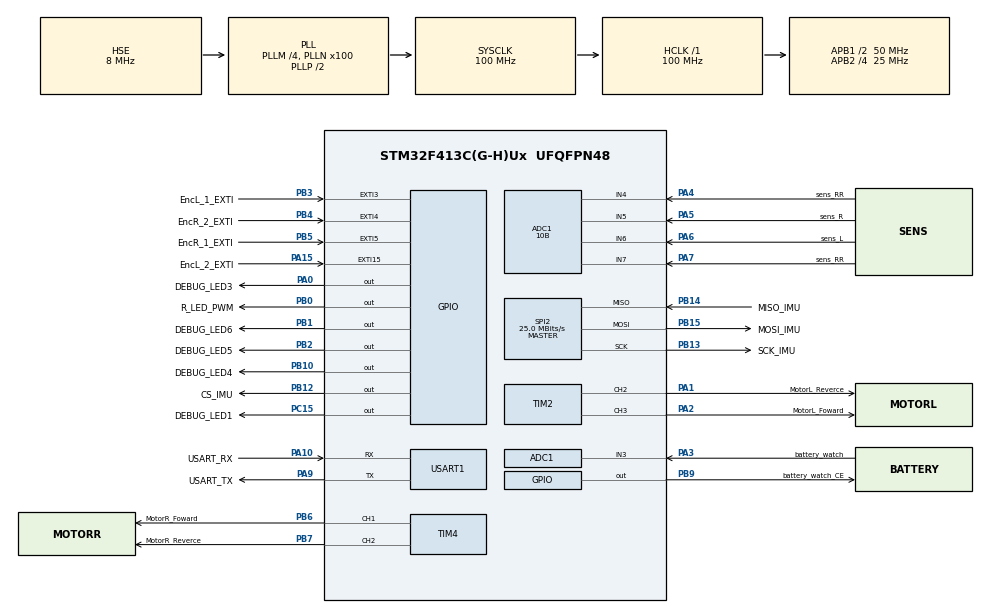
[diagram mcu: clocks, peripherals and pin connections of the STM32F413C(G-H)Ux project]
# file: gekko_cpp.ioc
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ADC1.Channel-0\#ChannelRegularConversion=ADC_CHANNEL_3
ADC1.Channel-1\#ChannelInjectedConversion=ADC_CHANNEL_3
ADC1.Channel-5\#ChannelRegularConversion=ADC_CHANNEL_3
ADC1.Channel-6\#ChannelRegularConversion=ADC_CHANNEL_3
ADC1.Channel-7\#ChannelRegularConversion=ADC_CHANNEL_3
ADC1.Channel-8\#ChannelRegularConversion=ADC_CHANNEL_3
ADC1.DiscontinuousConvMode=DISABLE
ADC1.InjNumberOfConversion=1
ADC1.InjectedOffset-1\#ChannelInjectedConversion=0
ADC1.InjectedRank-1\#ChannelInjectedConversion=1
ADC1.NbrOfConversion=5
ADC1.NbrOfConversionFlag=1
ADC1.Rank-0\#ChannelRegularConversion=1
ADC1.Rank-5\#ChannelRegularConversion=2
ADC1.Rank-6\#ChannelRegularConversion=3
ADC1.Rank-7\#ChannelRegularConversion=4
ADC1.Rank-8\#ChannelRegularConversion=5
ADC1.Resolution=ADC_RESOLUTION_10B
ADC1.SamplingTime-0\#ChannelRegularConversion=ADC_SAMPLETIME_3CYCLES
ADC1.SamplingTime-1\#ChannelInjectedConversion=ADC_SAMPLETIME_3CYCLES
ADC1.SamplingTime-5\#ChannelRegularConversion=ADC_SAMPLETIME_3CYCLES
ADC1.SamplingTime-6\#ChannelRegularConversion=ADC_SAMPLETIME_3CYCLES
ADC1.SamplingTime-7\#ChannelRegularConversion=ADC_SAMPLETIME_3CYCLES
ADC1.SamplingTime-8\#ChannelRegularConversion=ADC_SAMPLETIME_3CYCLES
ADC1.ScanConvMode=ENABLE
ADC1.master=1
Dma.ADC1.0.Direction=DMA_PERIPH_TO_MEMORY
Dma.ADC1.0.FIFOMode=DMA_FIFOMODE_DISABLE
Dma.ADC1.0.Instance=DMA2_Stream0
Dma.ADC1.0.MemDataAlignment=DMA_MDATAALIGN_HALFWORD
Dma.ADC1.0.MemInc=DMA_MINC_ENABLE
Dma.ADC1.0.Mode=DMA_NORMAL
Dma.ADC1.0.PeriphDataAlignment=DMA_PDATAALIGN_HALFWORD
Dma.ADC1.0.PeriphInc=DMA_PINC_DISABLE
Dma.ADC1.0.Priority=DMA_PRIORITY_LOW
Dma.Request0=ADC1
Mcu.Family=STM32F4
Mcu.Name=STM32F413C(G-H)Ux
Mcu.Package=UFQFPN48
NVIC.DMA2_Stream0_IRQn=true\:0\:0\:false\:false\:true\:false\:true
NVIC.PriorityGroup=NVIC_PRIORITYGROUP_4
PA0.GPIO_Label=DEBUG_LED3
PA0.Signal=GPIO_Output
PA1.GPIO_Label=MotorL_Reverce
PA1.Signal=S_TIM2_CH2
PA10.GPIO_Label=USART_RX
PA10.Mode=Asynchronous
PA10.Signal=USART1_RX
PA13.Mode=Serial_Wire
PA13.Signal=SYS_JTMS-SWDIO
PA14.Mode=Serial_Wire
PA14.Signal=SYS_JTCK-SWCLK
PA15.GPIO_Label=EncL_2_EXTI
PA15.Signal=GPXTI15
PA2.GPIO_Label=MotorL_Foward
PA2.Signal=S_TIM2_CH3
PA3.GPIO_Label=battery_watch
PA3.Signal=ADCx_IN3
PA4.GPIO_Label=sens_RR
PA4.Signal=ADCx_IN4
PA5.GPIO_Label=sens_R
PA5.Signal=ADCx_IN5
PA6.GPIO_Label=sens_L
PA6.Signal=ADCx_IN6
PA7.GPIO_Label=sens_RR
PA7.Signal=ADCx_IN7
PA9.GPIO_Label=USART_TX
PA9.Mode=Asynchronous
PA9.Signal=USART1_TX
PB0.GPIO_Label=R_LED_PWM
PB0.Signal=GPIO_Output
PB1.GPIO_Label=DEBUG_LED6
PB1.Signal=GPIO_Output
PB10.GPIO_Label=DEBUG_LED4
PB10.Signal=GPIO_Output
PB12.GPIO_Label=CS_IMU
PB12.Signal=GPIO_Output
PB13.GPIO_Label=SCK_IMU
PB13.Mode=Full_Duplex_Master
PB13.Signal=SPI2_SCK
PB14.GPIO_Label=MISO_IMU
PB14.Mode=Full_Duplex_Master
PB14.Signal=SPI2_MISO
PB15.GPIO_Label=MOSI_IMU
PB15.Mode=Full_Duplex_Master
PB15.Signal=SPI2_MOSI
PB2.GPIO_Label=DEBUG_LED5
PB2.Signal=GPIO_Output
PB3.GPIO_Label=EncL_1_EXTI
PB3.Signal=GPXTI3
PB4.GPIO_Label=EncR_2_EXTI
PB4.Signal=GPXTI4
PB5.GPIO_Label=EncR_1_EXTI
PB5.Signal=GPXTI5
PB6.GPIO_Label=MotorR_Foward
PB6.Signal=S_TIM4_CH1
PB7.GPIO_Label=MotorR_Reverce
PB7.Signal=S_TIM4_CH2
PB9.GPIO_Label=battery_watch_CE
PB9.Signal=GPIO_Output
PC15-OSC32_OUT.GPIO_Label=DEBUG_LED1
PC15-OSC32_OUT.Signal=GPIO_Output
PH0\ -\ OSC_IN.Mode=HSE-External-Oscillator
PH0\ -\ OSC_IN.Signal=RCC_OSC_IN
PH1\ -\ OSC_OUT.Mode=HSE-External-Oscillator
PH1\ -\ OSC_OUT.Signal=RCC_OSC_OUT
ProjectManager.HeapSize=0x200
ProjectManager.StackSize=0x400
ProjectManager.TargetToolchain=STM32CubeIDE
RCC.AHBFreq_Value=100000000
RCC.APB1CLKDivider=RCC_HCLK_DIV2
RCC.APB1Freq_Value=50000000
RCC.APB1TimFreq_Value=100000000
RCC.APB2CLKDivider=RCC_HCLK_DIV4
RCC.APB2Freq_Value=25000000
RCC.APB2TimFreq_Value=50000000
RCC.CortexFreq_Value=100000000
RCC.DATA_CACHE_ENABLE=1
RCC.HCLKFreq_Value=100000000
RCC.HSE_VALUE=8000000
RCC.PLLM=4
RCC.PLLN=100
RCC.PLLSourceVirtual=RCC_PLLSOURCE_HSE
RCC.PREFETCH_ENABLE=1
RCC.RCC_TIM_PRescaler_Selection=RCC_TIMPRES_DESACTIVATED
RCC.SYSCLKFreq_VALUE=100000000
RCC.SYSCLKSource=RCC_SYSCLKSOURCE_PLLCLK
RCC.USBFreq_Value=100000000
RCC.VCOOutputFreq_Value=200000000
SH.ADCx_IN3.0=ADC1_IN3,IN3
SH.ADCx_IN4.0=ADC1_IN4,IN4
SH.ADCx_IN5.0=ADC1_IN5,IN5
SH.ADCx_IN6.0=ADC1_IN6,IN6
SH.ADCx_IN7.0=ADC1_IN7,IN7
SH.S_TIM2_CH2.0=TIM2_CH2,PWM Generation2 CH2
SH.S_TIM2_CH3.0=TIM2_CH3,PWM Generation3 CH3
SH.S_TIM4_CH1.0=TIM4_CH1,PWM Generation1 CH1
SH.S_TIM4_CH2.0=TIM4_CH2,PWM Generation2 CH2
SPI2.BaudRatePrescaler=SPI_BAUDRATEPRESCALER_2
SPI2.CalculateBaudRate=25.0 MBits/s
SPI2.Direction=SPI_DIRECTION_2LINES
SPI2.Mode=SPI_MODE_MASTER
SPI2.VirtualType=VM_MASTER
TIM2.Channel-PWM\ Generation2\ CH2=TIM_CHANNEL_2
TIM2.Channel-PWM\ Generation3\ CH3=TIM_CHANNEL_3
TIM4.Channel-PWM\ Generation1\ CH1=TIM_CHANNEL_1
TIM4.Channel-PWM\ Generation2\ CH2=TIM_CHANNEL_2
USART1.VirtualMode=VM_ASYNC
board=custom

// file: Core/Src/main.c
/* USER CODE BEGIN Header */
/**
  ******************************************************************************
  * @file           : main.c
  * @brief          : Main program body
  ******************************************************************************
  * @attention
  *
  * <h2><center>&copy; Copyright (c) 2020 STMicroelectronics.
  * All rights reserved.</center></h2>
  *
  * This software component is licensed by ST under BSD 3-Clause license,
  * the "License"; You may not use this file except in compliance with the
  * License. You may obtain a copy of the License at:
  *                        opensource.org/licenses/BSD-3-Clause
  *
  ******************************************************************************
  */
/* USER CODE END Header */

#include "main.h"

ADC_HandleTypeDef hadc1;
DMA_HandleTypeDef hdma_adc1;

SPI_HandleTypeDef hspi2;

TIM_HandleTypeDef htim2;
TIM_HandleTypeDef htim4;

UART_HandleTypeDef huart1;

void SystemClock_Config(void);
static void MX_GPIO_Init(void);
static void MX_DMA_Init(void);
static void MX_ADC1_Init(void);
static void MX_SPI2_Init(void);
static void MX_TIM2_Init(void);
static void MX_TIM4_Init(void);
static void MX_USART1_UART_Init(void);

int main(void)
{

  /* MCU Configuration--------------------------------------------------------*/

  /* Reset of all peripherals, Initializes the Flash interface and the Systick. */
  HAL_Init();

  /* Configure the system clock */
  SystemClock_Config();

  /* Initialize all configured peripherals */
  MX_GPIO_Init();
  MX_DMA_Init();
  MX_ADC1_Init();
  MX_SPI2_Init();
  MX_TIM2_Init();
  MX_TIM4_Init();
  MX_USART1_UART_Init();

  /* Infinite loop */
  while (1)
  {

    /* USER CODE BEGIN 3 */
	  HAL_GPIO_TogglePin(GPIOB, DEBUG_LED5_Pin);
	  HAL_Delay(100);

  }
  /* USER CODE END 3 */
}

void SystemClock_Config(void)
{
  RCC_OscInitTypeDef RCC_OscInitStruct = {0};
  RCC_ClkInitTypeDef RCC_ClkInitStruct = {0};

  /** Configure the main internal regulator output voltage
  */
  __HAL_RCC_PWR_CLK_ENABLE();
  __HAL_PWR_VOLTAGESCALING_CONFIG(PWR_REGULATOR_VOLTAGE_SCALE1);
  /** Initializes the CPU, AHB and APB busses clocks
  */
  RCC_OscInitStruct.OscillatorType = RCC_OSCILLATORTYPE_HSE;
  RCC_OscInitStruct.HSEState = RCC_HSE_ON;
  RCC_OscInitStruct.PLL.PLLState = RCC_PLL_ON;
  RCC_OscInitStruct.PLL.PLLSource = RCC_PLLSOURCE_HSE;
  RCC_OscInitStruct.PLL.PLLM = 4;
  RCC_OscInitStruct.PLL.PLLN = 100;
  RCC_OscInitStruct.PLL.PLLP = RCC_PLLP_DIV2;
  RCC_OscInitStruct.PLL.PLLQ = 2;
  RCC_OscInitStruct.PLL.PLLR = 2;
  if (HAL_RCC_OscConfig(&RCC_OscInitStruct) != HAL_OK)
  {
    Error_Handler();
  }
  /** Initializes the CPU, AHB and APB busses clocks
  */
  RCC_ClkInitStruct.ClockType = RCC_CLOCKTYPE_HCLK|RCC_CLOCKTYPE_SYSCLK
                              |RCC_CLOCKTYPE_PCLK1|RCC_CLOCKTYPE_PCLK2;
  RCC_ClkInitStruct.SYSCLKSource = RCC_SYSCLKSOURCE_PLLCLK;
  RCC_ClkInitStruct.AHBCLKDivider = RCC_SYSCLK_DIV1;
  RCC_ClkInitStruct.APB1CLKDivider = RCC_HCLK_DIV2;
  RCC_ClkInitStruct.APB2CLKDivider = RCC_HCLK_DIV4;

  if (HAL_RCC_ClockConfig(&RCC_ClkInitStruct, FLASH_LATENCY_3) != HAL_OK)
  {
    Error_Handler();
  }
}

static void MX_ADC1_Init(void)
{

  ADC_ChannelConfTypeDef sConfig = {0};
  ADC_InjectionConfTypeDef sConfigInjected = {0};

  /** Configure the global features of the ADC (Clock, Resolution, Data Alignment and number of conversion)
  */
  hadc1.Instance = ADC1;
  hadc1.Init.ClockPrescaler = ADC_CLOCK_SYNC_PCLK_DIV2;
  hadc1.Init.Resolution = ADC_RESOLUTION_10B;
  hadc1.Init.ScanConvMode = ENABLE;
  hadc1.Init.ContinuousConvMode = DISABLE;
  hadc1.Init.DiscontinuousConvMode = DISABLE;
  hadc1.Init.ExternalTrigConvEdge = ADC_EXTERNALTRIGCONVEDGE_NONE;
  hadc1.Init.ExternalTrigConv = ADC_SOFTWARE_START;
  hadc1.Init.DataAlign = ADC_DATAALIGN_RIGHT;
  hadc1.Init.NbrOfConversion = 5;
  hadc1.Init.DMAContinuousRequests = DISABLE;
  hadc1.Init.EOCSelection = ADC_EOC_SINGLE_CONV;
  if (HAL_ADC_Init(&hadc1) != HAL_OK)
  {
    Error_Handler();
  }
  /** Configure for the selected ADC regular channel its corresponding rank in the sequencer and its sample time.
  */
  sConfig.Channel = ADC_CHANNEL_3;
  sConfig.Rank = 1;
  sConfig.SamplingTime = ADC_SAMPLETIME_3CYCLES;
  if (HAL_ADC_ConfigChannel(&hadc1, &sConfig) != HAL_OK)
  {
    Error_Handler();
  }
  /** Configure for the selected ADC regular channel its corresponding rank in the sequencer and its sample time.
  */
  sConfig.Rank = 2;
  if (HAL_ADC_ConfigChannel(&hadc1, &sConfig) != HAL_OK)
  {
    Error_Handler();
  }
  /** Configure for the selected ADC regular channel its corresponding rank in the sequencer and its sample time.
  */
  sConfig.Rank = 3;
  if (HAL_ADC_ConfigChannel(&hadc1, &sConfig) != HAL_OK)
  {
    Error_Handler();
  }
  /** Configure for the selected ADC regular channel its corresponding rank in the sequencer and its sample time.
  */
  sConfig.Rank = 4;
  if (HAL_ADC_ConfigChannel(&hadc1, &sConfig) != HAL_OK)
  {
    Error_Handler();
  }
  /** Configure for the selected ADC regular channel its corresponding rank in the sequencer and its sample time.
  */
  sConfig.Rank = 5;
  if (HAL_ADC_ConfigChannel(&hadc1, &sConfig) != HAL_OK)
  {
    Error_Handler();
  }
  /** Configures for the selected ADC injected channel its corresponding rank in the sequencer and its sample time
  */
  sConfigInjected.InjectedChannel = ADC_CHANNEL_3;
  sConfigInjected.InjectedRank = 1;
  sConfigInjected.InjectedNbrOfConversion = 1;
  sConfigInjected.InjectedSamplingTime = ADC_SAMPLETIME_3CYCLES;
  sConfigInjected.ExternalTrigInjecConvEdge = ADC_EXTERNALTRIGINJECCONVEDGE_NONE;
  sConfigInjected.ExternalTrigInjecConv = ADC_INJECTED_SOFTWARE_START;
  sConfigInjected.AutoInjectedConv = DISABLE;
  sConfigInjected.InjectedDiscontinuousConvMode = DISABLE;
  sConfigInjected.InjectedOffset = 0;
  if (HAL_ADCEx_InjectedConfigChannel(&hadc1, &sConfigInjected) != HAL_OK)
  {
    Error_Handler();
  }

}

static void MX_SPI2_Init(void)
{

  /* SPI2 parameter configuration*/
  hspi2.Instance = SPI2;
  hspi2.Init.Mode = SPI_MODE_MASTER;
  hspi2.Init.Direction = SPI_DIRECTION_2LINES;
  hspi2.Init.DataSize = SPI_DATASIZE_8BIT;
  hspi2.Init.CLKPolarity = SPI_POLARITY_LOW;
  hspi2.Init.CLKPhase = SPI_PHASE_1EDGE;
  hspi2.Init.NSS = SPI_NSS_SOFT;
  hspi2.Init.BaudRatePrescaler = SPI_BAUDRATEPRESCALER_2;
  hspi2.Init.FirstBit = SPI_FIRSTBIT_MSB;
  hspi2.Init.TIMode = SPI_TIMODE_DISABLE;
  hspi2.Init.CRCCalculation = SPI_CRCCALCULATION_DISABLE;
  hspi2.Init.CRCPolynomial = 10;
  if (HAL_SPI_Init(&hspi2) != HAL_OK)
  {
    Error_Handler();
  }

}

static void MX_TIM2_Init(void)
{

  TIM_MasterConfigTypeDef sMasterConfig = {0};
  TIM_OC_InitTypeDef sConfigOC = {0};

  htim2.Instance = TIM2;
  htim2.Init.Prescaler = 0;
  htim2.Init.CounterMode = TIM_COUNTERMODE_UP;
  htim2.Init.Period = 0;
  htim2.Init.ClockDivision = TIM_CLOCKDIVISION_DIV1;
  htim2.Init.AutoReloadPreload = TIM_AUTORELOAD_PRELOAD_DISABLE;
  if (HAL_TIM_PWM_Init(&htim2) != HAL_OK)
  {
    Error_Handler();
  }
  sMasterConfig.MasterOutputTrigger = TIM_TRGO_RESET;
  sMasterConfig.MasterSlaveMode = TIM_MASTERSLAVEMODE_DISABLE;
  if (HAL_TIMEx_MasterConfigSynchronization(&htim2, &sMasterConfig) != HAL_OK)
  {
    Error_Handler();
  }
  sConfigOC.OCMode = TIM_OCMODE_PWM1;
  sConfigOC.Pulse = 0;
  sConfigOC.OCPolarity = TIM_OCPOLARITY_HIGH;
  sConfigOC.OCFastMode = TIM_OCFAST_DISABLE;
  if (HAL_TIM_PWM_ConfigChannel(&htim2, &sConfigOC, TIM_CHANNEL_2) != HAL_OK)
  {
    Error_Handler();
  }
  if (HAL_TIM_PWM_ConfigChannel(&htim2, &sConfigOC, TIM_CHANNEL_3) != HAL_OK)
  {
    Error_Handler();
  }
  HAL_TIM_MspPostInit(&htim2);

}

static void MX_TIM4_Init(void)
{

  TIM_MasterConfigTypeDef sMasterConfig = {0};
  TIM_OC_InitTypeDef sConfigOC = {0};

  htim4.Instance = TIM4;
  htim4.Init.Prescaler = 0;
  htim4.Init.CounterMode = TIM_COUNTERMODE_UP;
  htim4.Init.Period = 0;
  htim4.Init.ClockDivision = TIM_CLOCKDIVISION_DIV1;
  htim4.Init.AutoReloadPreload = TIM_AUTORELOAD_PRELOAD_DISABLE;
  if (HAL_TIM_PWM_Init(&htim4) != HAL_OK)
  {
    Error_Handler();
  }
  sMasterConfig.MasterOutputTrigger = TIM_TRGO_RESET;
  sMasterConfig.MasterSlaveMode = TIM_MASTERSLAVEMODE_DISABLE;
  if (HAL_TIMEx_MasterConfigSynchronization(&htim4, &sMasterConfig) != HAL_OK)
  {
    Error_Handler();
  }
  sConfigOC.OCMode = TIM_OCMODE_PWM1;
  sConfigOC.Pulse = 0;
  sConfigOC.OCPolarity = TIM_OCPOLARITY_HIGH;
  sConfigOC.OCFastMode = TIM_OCFAST_DISABLE;
  if (HAL_TIM_PWM_ConfigChannel(&htim4, &sConfigOC, TIM_CHANNEL_1) != HAL_OK)
  {
    Error_Handler();
  }
  if (HAL_TIM_PWM_ConfigChannel(&htim4, &sConfigOC, TIM_CHANNEL_2) != HAL_OK)
  {
    Error_Handler();
  }
  HAL_TIM_MspPostInit(&htim4);

}

static void MX_USART1_UART_Init(void)
{

  huart1.Instance = USART1;
  huart1.Init.BaudRate = 115200;
  huart1.Init.WordLength = UART_WORDLENGTH_8B;
  huart1.Init.StopBits = UART_STOPBITS_1;
  huart1.Init.Parity = UART_PARITY_NONE;
  huart1.Init.Mode = UART_MODE_TX_RX;
  huart1.Init.HwFlowCtl = UART_HWCONTROL_NONE;
  huart1.Init.OverSampling = UART_OVERSAMPLING_16;
  if (HAL_UART_Init(&huart1) != HAL_OK)
  {
    Error_Handler();
  }

}

static void MX_DMA_Init(void)
{

  /* DMA controller clock enable */
  __HAL_RCC_DMA2_CLK_ENABLE();

  /* DMA interrupt init */
  /* DMA2_Stream0_IRQn interrupt configuration */
  HAL_NVIC_SetPriority(DMA2_Stream0_IRQn, 0, 0);
  HAL_NVIC_EnableIRQ(DMA2_Stream0_IRQn);

}

static void MX_GPIO_Init(void)
{
  GPIO_InitTypeDef GPIO_InitStruct = {0};

  /* GPIO Ports Clock Enable */
  __HAL_RCC_GPIOC_CLK_ENABLE();
  __HAL_RCC_GPIOH_CLK_ENABLE();
  __HAL_RCC_GPIOA_CLK_ENABLE();
  __HAL_RCC_GPIOB_CLK_ENABLE();

  /*Configure GPIO pin Output Level */
  HAL_GPIO_WritePin(DEBUG_LED1_GPIO_Port, DEBUG_LED1_Pin, GPIO_PIN_RESET);

  /*Configure GPIO pin Output Level */
  HAL_GPIO_WritePin(DEBUG_LED3_GPIO_Port, DEBUG_LED3_Pin, GPIO_PIN_RESET);

  /*Configure GPIO pin Output Level */
  HAL_GPIO_WritePin(GPIOB, R_LED_PWM_Pin|DEBUG_LED6_Pin|DEBUG_LED5_Pin|DEBUG_LED4_Pin
                          |CS_IMU_Pin|battery_watch_CE_Pin, GPIO_PIN_RESET);

  /*Configure GPIO pin : DEBUG_LED1_Pin */
  GPIO_InitStruct.Pin = DEBUG_LED1_Pin;
  GPIO_InitStruct.Mode = GPIO_MODE_OUTPUT_PP;
  GPIO_InitStruct.Pull = GPIO_NOPULL;
  GPIO_InitStruct.Speed = GPIO_SPEED_FREQ_LOW;
  HAL_GPIO_Init(DEBUG_LED1_GPIO_Port, &GPIO_InitStruct);

  /*Configure GPIO pin : DEBUG_LED3_Pin */
  GPIO_InitStruct.Pin = DEBUG_LED3_Pin;
  GPIO_InitStruct.Mode = GPIO_MODE_OUTPUT_PP;
  GPIO_InitStruct.Pull = GPIO_NOPULL;
  GPIO_InitStruct.Speed = GPIO_SPEED_FREQ_LOW;
  HAL_GPIO_Init(DEBUG_LED3_GPIO_Port, &GPIO_InitStruct);

  /*Configure GPIO pins : R_LED_PWM_Pin DEBUG_LED6_Pin DEBUG_LED5_Pin DEBUG_LED4_Pin
                           CS_IMU_Pin battery_watch_CE_Pin */
  GPIO_InitStruct.Pin = R_LED_PWM_Pin|DEBUG_LED6_Pin|DEBUG_LED5_Pin|DEBUG_LED4_Pin
                          |CS_IMU_Pin|battery_watch_CE_Pin;
  GPIO_InitStruct.Mode = GPIO_MODE_OUTPUT_PP;
  GPIO_InitStruct.Pull = GPIO_NOPULL;
  GPIO_InitStruct.Speed = GPIO_SPEED_FREQ_LOW;
  HAL_GPIO_Init(GPIOB, &GPIO_InitStruct);

  /*Configure GPIO pin : EncL_2_EXTI_Pin */
  GPIO_InitStruct.Pin = EncL_2_EXTI_Pin;
  GPIO_InitStruct.Mode = GPIO_MODE_IT_RISING;
  GPIO_InitStruct.Pull = GPIO_NOPULL;
  HAL_GPIO_Init(EncL_2_EXTI_GPIO_Port, &GPIO_InitStruct);

  /*Configure GPIO pins : EncL_1_EXTI_Pin EncR_2_EXTI_Pin EncR_1_EXTI_Pin */
  GPIO_InitStruct.Pin = EncL_1_EXTI_Pin|EncR_2_EXTI_Pin|EncR_1_EXTI_Pin;
  GPIO_InitStruct.Mode = GPIO_MODE_IT_RISING;
  GPIO_InitStruct.Pull = GPIO_NOPULL;
  HAL_GPIO_Init(GPIOB, &GPIO_InitStruct);

}

void Error_Handler(void)
{
}

/************************ (C) COPYRIGHT STMicroelectronics *****END OF FILE****/
